# HC32F472 register map
File version: 1.0
CPU: CM4 r0p1, little endian, MPU, FPU, 4 interrupt priority bits
Registers are 32-bit, read-write, reset 0x0 unless marked. A register's access mark holds for its fields unless they carry their own. Offsets are from the block's base; [hi:lo] are bit positions; {n}, {i} and the like mark numbered series; 'fields as' and 'values as' point back to an identical list.

## QSPI
Base 0x9C000000
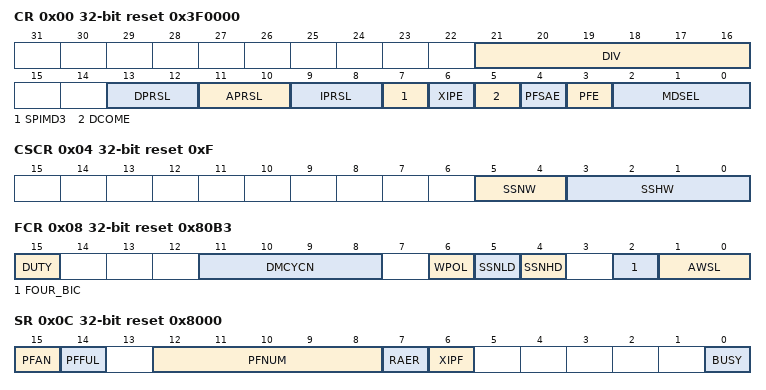
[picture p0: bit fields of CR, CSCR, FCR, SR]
0x00 CR reset 0x3F0000
  [21:16] DIV, [13:12] DPRSL, [11:10] APRSL, [9:8] IPRSL, [7] SPIMD3, [6] XIPE, [5] DCOME, [4] PFSAE, [3] PFE, [2:0] MDSEL
0x04 CSCR reset 0xF
  [5:4] SSNW, [3:0] SSHW
0x08 FCR reset 0x80B3
  [15] DUTY, [11:8] DMCYCN, [6] WPOL, [5] SSNLD, [4] SSNHD, [2] FOUR_BIC, [1:0] AWSL
0x0C SR reset 0x8000
  [15] PFAN, [14] PFFUL, [12:8] PFNUM, [7] RAER, [6] XIPF, [0] BUSY
0x10 DCOM
  [7:0] DCOM
0x14 CCMD
  [7:0] RIC
0x18 XCMD reset 0xFF
  [7:0] XIPMC
0x24 SR2 wo
  [7] RAERCLR
0x804 EXAR
  [31:26] EXADR

## RMU
Base 0x4004CCE0
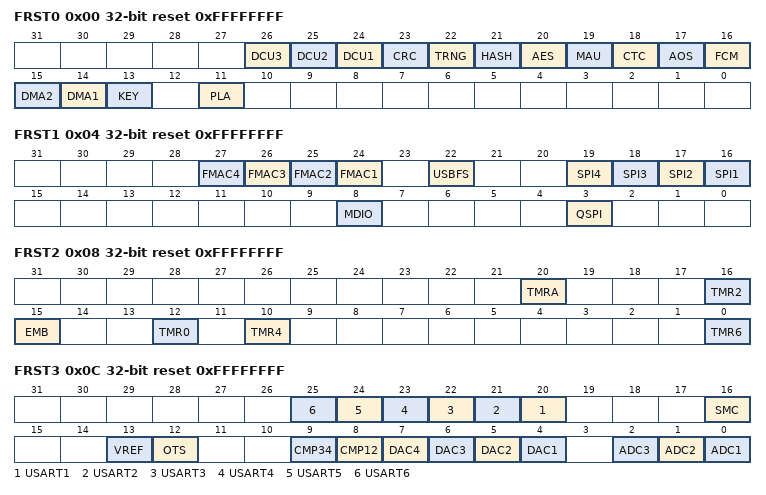
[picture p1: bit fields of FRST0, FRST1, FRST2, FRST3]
0x00 FRST0 reset 0xFFFFFFFF
  [26] DCU3, [25] DCU2, [24] DCU1, [23] CRC, [22] TRNG, [21] HASH, [20] AES, [19] MAU, [18] CTC, [17] AOS, [16] FCM, [15] DMA2, [14] DMA1, [13] KEY, [11] PLA
0x04 FRST1 reset 0xFFFFFFFF
  [n+23] FMAC{n} (n=1..4), [22] USBFS, [n+15] SPI{n} (n=1..4), [8] MDIO, [3] QSPI
0x08 FRST2 reset 0xFFFFFFFF
  [20] TMRA, [16] TMR2, [15] EMB, [12] TMR0, [10] TMR4, [0] TMR6
0x0C FRST3 reset 0xFFFFFFFF
  [n+19] USART{n} (n=1..6), [16] SMC, [13] VREF, [12] OTS, [9] CMP34, [8] CMP12, [n+3] DAC{n} (n=1..4), [2] ADC3, [1] ADC2, [0] ADC1
0x10 PRSTCR0 8-bit reset 0x40
  [5] LKUPREN
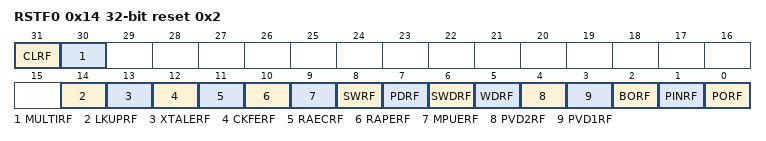
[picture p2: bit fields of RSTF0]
0x14 RSTF0 reset 0x2
  [31] CLRF, [30] MULTIRF, [14] LKUPRF, [13] XTALERF, [12] CKFERF, [11] RAECRF, [10] RAPERF, [9] MPUERF, [8] SWRF, [7] PDRF, [6] SWDRF, [5] WDRF, [4] PVD2RF, [3] PVD1RF, [2] BORF, [1] PINRF, [0] PORF

## RTC
Base 0x4004C000
0x00 CR0 8-bit
  [0] RESET
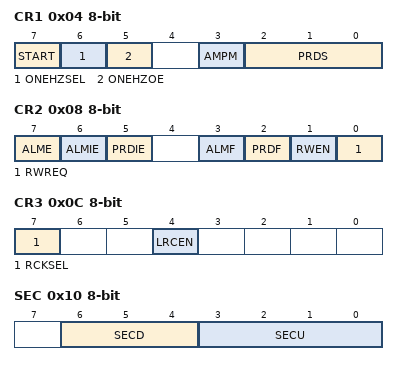
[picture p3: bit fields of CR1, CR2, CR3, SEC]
0x04 CR1 8-bit
  [7] START, [6] ONEHZSEL, [5] ONEHZOE, [3] AMPM, [2:0] PRDS
0x08 CR2 8-bit
  [7] ALME, [6] ALMIE, [5] PRDIE, [3] ALMF, [2] PRDF, [1] RWEN, [0] RWREQ
0x0C CR3 8-bit
  [7] RCKSEL, [4] LRCEN
0x10 SEC 8-bit
  [6:4] SECD, [3:0] SECU
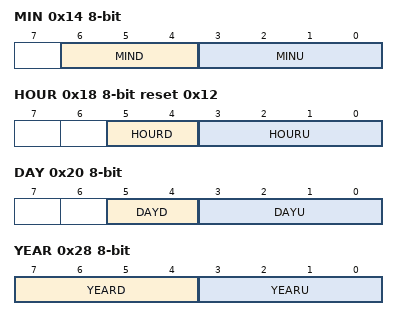
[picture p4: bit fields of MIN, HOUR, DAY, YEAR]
0x14 MIN 8-bit
  [6:4] MIND, [3:0] MINU
0x18 HOUR 8-bit reset 0x12
  [5:4] HOURD, [3:0] HOURU
0x1C WEEK 8-bit
  [2:0] WEEK
0x20 DAY 8-bit
  [5:4] DAYD, [3:0] DAYU
0x24 MON 8-bit
  [4:0] MON
0x28 YEAR 8-bit
  [7:4] YEARD, [3:0] YEARU
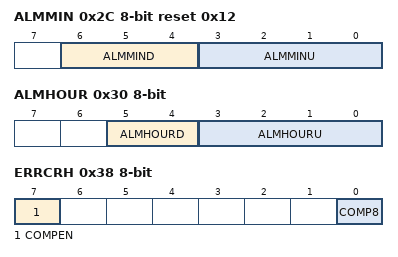
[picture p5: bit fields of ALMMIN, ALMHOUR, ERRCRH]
0x2C ALMMIN 8-bit reset 0x12
  [6:4] ALMMIND, [3:0] ALMMINU
0x30 ALMHOUR 8-bit
  [5:4] ALMHOURD, [3:0] ALMHOURU
0x34 ALMWEEK 8-bit
  [6:0] ALMWEEK
0x38 ERRCRH 8-bit
  [7] COMPEN, [0] COMP8
0x3C ERRCRL 8-bit reset 0x20

## SMC
Base 0x88000000
0x00 STSR ro reset 0x1
  [0] STATUS
0x08 STCR0 wo
  [2] LPWIR
0x0C STCR1 wo
  [2] LPWOR
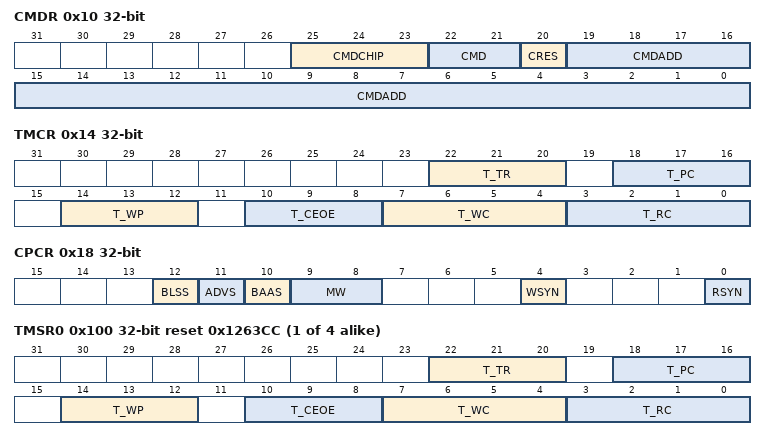
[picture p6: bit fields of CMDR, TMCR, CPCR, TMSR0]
0x10 CMDR wo
  [25:23] CMDCHIP, [22:21] CMD, [20] CRES, [19:0] CMDADD
0x14 TMCR wo
  [22:20] T_TR, [18:16] T_PC, [14:12] T_WP, [10:8] T_CEOE, [7:4] T_WC, [3:0] T_RC
0x18 CPCR wo
  [12] BLSS, [11] ADVS, [10] BAAS, [9:8] MW, [4] WSYN, [0] RSYN
0x20 RFTR
  [3:0] REFPRD
{0x100+0x20*i} TMSR{i} ro reset 0x1263CC (i=0..3)
  fields as TMCR
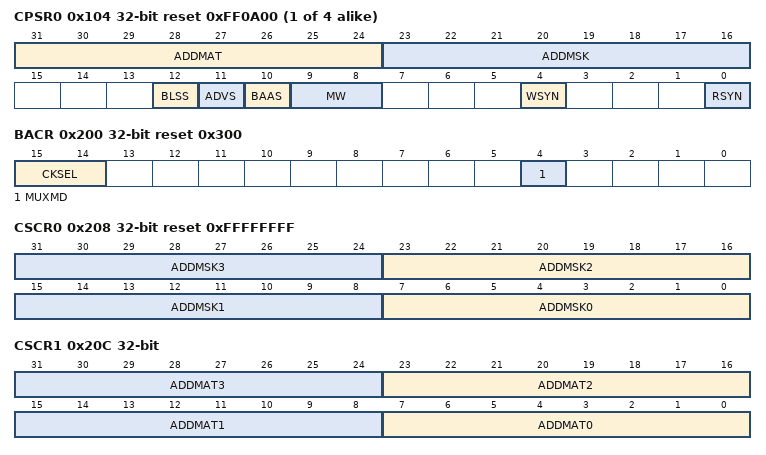
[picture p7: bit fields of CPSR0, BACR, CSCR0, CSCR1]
{0x104+0x20*i} CPSR{i} ro reset 0xFF0A00 (i=0..3)
  [31:24] ADDMAT, [23:16] ADDMSK, [12] BLSS, [11] ADVS, [10] BAAS, [9:8] MW, [4] WSYN, [0] RSYN
0x200 BACR reset 0x300
  [15:14] CKSEL, [4] MUXMD
0x208 CSCR0 reset 0xFFFFFFFF
  [8n+7:8n] ADDMSK{n} (n=0..3)
0x20C CSCR1
  [8n+7:8n] ADDMAT{n} (n=0..3)

## SPI1 — desc SPI
Base 0x4001C000
Same registers: SPI2 0x4001C400, SPI3 0x40020000, SPI4 0x40020400
0x00 DR
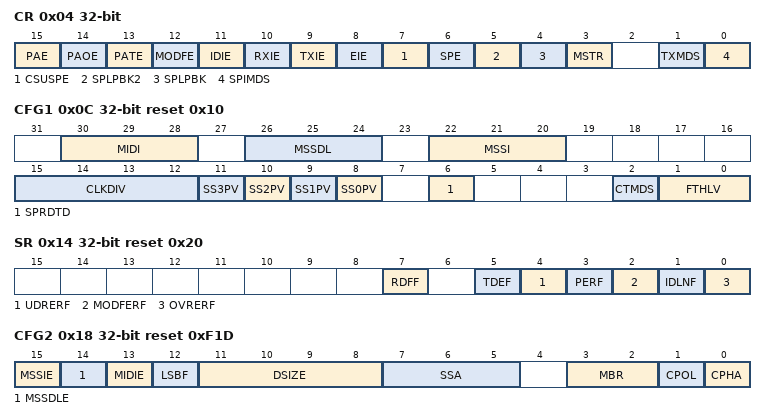
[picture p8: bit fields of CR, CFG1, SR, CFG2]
0x04 CR
  [15] PAE, [14] PAOE, [13] PATE, [12] MODFE, [11] IDIE, [10] RXIE, [9] TXIE, [8] EIE, [7] CSUSPE, [6] SPE, [5] SPLPBK2, [4] SPLPBK, [3] MSTR, [1] TXMDS, [0] SPIMDS
0x0C CFG1 reset 0x10
  [30:28] MIDI, [26:24] MSSDL, [22:20] MSSI, [15:12] CLKDIV, [n+8] SS{n}PV (n=0..3), [6] SPRDTD, [2] CTMDS, [1:0] FTHLV
0x14 SR reset 0x20
  [7] RDFF ro, [5] TDEF ro, [4] UDRERF, [3] PERF, [2] MODFERF, [1] IDLNF ro, [0] OVRERF
0x18 CFG2 reset 0xF1D
  [15] MSSIE, [14] MSSDLE, [13] MIDIE, [12] LSBF, [11:8] DSIZE, [7:5] SSA, [3:2] MBR, [1] CPOL, [0] CPHA

## SRAMC
Base 0x40050800
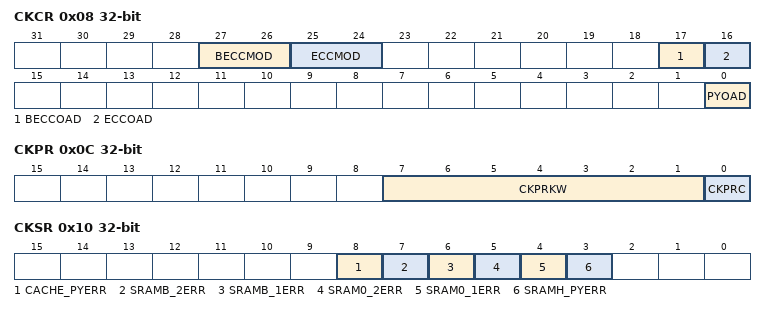
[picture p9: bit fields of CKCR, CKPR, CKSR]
0x08 CKCR
  [27:26] BECCMOD, [25:24] ECCMOD, [17] BECCOAD, [16] ECCOAD, [0] PYOAD
0x0C CKPR
  [7:1] CKPRKW, [0] CKPRC
0x10 CKSR
  [8] CACHE_PYERR, [7] SRAMB_2ERR, [6] SRAMB_1ERR, [5] SRAM0_2ERR, [4] SRAM0_1ERR, [3] SRAMH_PYERR
0x14 SRAM0_EIEN
  [0] EIEN
0x18 SRAM0_EIBIT0
0x1C SRAM0_EIBIT1
  [6:0] EIBIT
0x20 SRAM0_ECCERRADDR
  [14:0] ECCERRADDR
0x24 SRAMB_EIEN
  [0] EIEN
0x28 SRAMB_EIBIT0
0x2C SRAMB_EIBIT1
  [6:0] EIBIT
0x30 SRAMB_ECCERRADDR
  [11:0] ECCERRADDR
